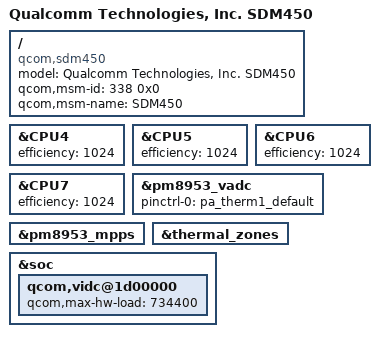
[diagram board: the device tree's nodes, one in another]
/*
 * Copyright (c) 2017-2018, 2021 The Linux Foundation. All rights reserved.
 *
 * This program is free software; you can redistribute it and/or modify
 * it under the terms of the GNU General Public License version 2 and
 * only version 2 as published by the Free Software Foundation.
 *
 * This program is distributed in the hope that it will be useful,
 * but WITHOUT ANY WARRANTY; without even the implied warranty of
 * MERCHANTABILITY or FITNESS FOR A PARTICULAR PURPOSE.  See the
 * GNU General Public License for more details.
 */

#include "msm8953.dtsi"

/ {
	model = "Qualcomm Technologies, Inc. SDM450";
	compatible = "qcom,sdm450";
	qcom,msm-id = <338 0x0>;
	qcom,msm-name = "SDM450";
};

&CPU4 {
	efficiency = <1024>;
};

&CPU5 {
	efficiency = <1024>;
};

&CPU6 {
	efficiency = <1024>;
};

&CPU7 {
	efficiency = <1024>;
};

&pm8953_vadc {
	pinctrl-0 = <&pa_therm1_default>;
	/delete-node/ chan@13;
};

&pm8953_mpps {
	/delete-node/ case_therm;
};

&thermal_zones {
	/delete-node/ case-therm-adc;
	/delete-node/ case-therm-step;
};
&soc {
	qcom,vidc@1d00000 {
		qcom,max-hw-load = <734400>; /* 1080p@60 dec + 1080p@30 enc */
	};
};
